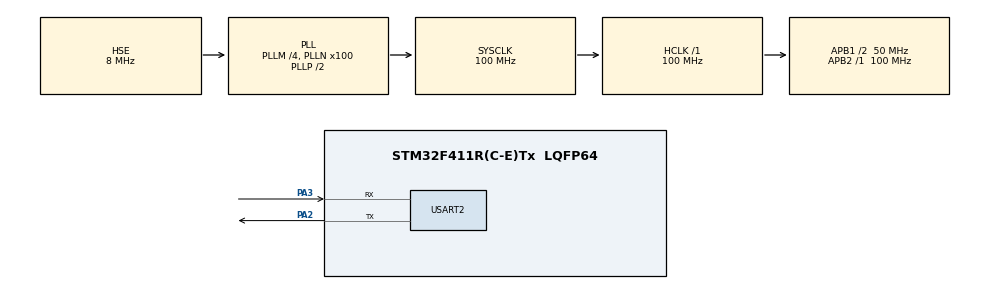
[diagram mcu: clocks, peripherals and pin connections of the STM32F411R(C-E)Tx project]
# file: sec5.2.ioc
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Mcu.Family=STM32F4
RCC.PLLSourceVirtual=RCC_PLLSOURCE_HSE
Dma.USART2_TX.1.Priority=DMA_PRIORITY_LOW
RCC.CortexFreq_Value=100000000
Dma.USART2_TX.1.FIFOMode=DMA_FIFOMODE_DISABLE
Dma.USART2_TX.1.MemInc=DMA_MINC_ENABLE
PH1\ -\ OSC_OUT.Mode=HSE-External-Clock-Source
Dma.USART2_RX.0.Direction=DMA_PERIPH_TO_MEMORY
RCC.APB1CLKDivider=RCC_HCLK_DIV2
Dma.USART2_TX.1.PeriphDataAlignment=DMA_PDATAALIGN_BYTE
NVIC.USART2_IRQn=true\:0\:0\:false\:false\:true\:true\:true
RCC.SYSCLKSource=RCC_SYSCLKSOURCE_PLLCLK
ProjectManager.StackSize=0x400
Dma.USART2_RX.0.Mode=DMA_NORMAL
PA3.Mode=Asynchronous
PA13.Signal=SYS_JTMS-SWDIO
PH0\ -\ OSC_IN.Mode=HSE-External-Clock-Source
PH0\ -\ OSC_IN.Signal=RCC_OSC_IN
ProjectManager.TargetToolchain=STM32CubeIDE
NVIC.DMA1_Stream5_IRQn=true\:0\:0\:false\:false\:true\:false\:true
Dma.USART2_RX.0.Priority=DMA_PRIORITY_LOW
Dma.USART2_RX.0.PeriphDataAlignment=DMA_PDATAALIGN_BYTE
RCC.HCLKFreq_Value=100000000
RCC.APB2TimFreq_Value=100000000
Dma.USART2_TX.1.Mode=DMA_NORMAL
RCC.LSE_VALUE=32768
RCC.AHBFreq_Value=100000000
RCC.HSE_VALUE=8000000
PH1\ -\ OSC_OUT.Signal=RCC_OSC_OUT
Dma.USART2_TX.1.PeriphInc=DMA_PINC_DISABLE
board=custom
RCC.VCOOutputFreq_Value=200000000
Dma.USART2_TX.1.Direction=DMA_MEMORY_TO_PERIPH
RCC.APB2Freq_Value=100000000
Dma.USART2_RX.0.MemDataAlignment=DMA_MDATAALIGN_BYTE
PA14.Mode=Serial_Wire
Dma.USART2_TX.1.Instance=DMA1_Stream6
Dma.USART2_RX.0.Instance=DMA1_Stream5
PA13.Mode=Serial_Wire
Mcu.Name=STM32F411R(C-E)Tx
Dma.USART2_RX.0.MemInc=DMA_MINC_ENABLE
PA2.Signal=USART2_TX
RCC.48MHZClocksFreq_Value=50000000
RCC.SYSCLKFreq_VALUE=100000000
Mcu.Package=LQFP64
Dma.USART2_RX.0.PeriphInc=DMA_PINC_DISABLE
USART2.VirtualMode=VM_ASYNC
Dma.USART2_RX.0.FIFOMode=DMA_FIFOMODE_DISABLE
PA14.Signal=SYS_JTCK-SWCLK
ProjectManager.HeapSize=0x200
RCC.HSI_VALUE=16000000
NVIC.PriorityGroup=NVIC_PRIORITYGROUP_4
RCC.PLLM=4
RCC.PLLN=100
Dma.Request1=USART2_TX
RCC.APB1TimFreq_Value=100000000
PA2.Mode=Asynchronous
Dma.USART2_TX.1.MemDataAlignment=DMA_MDATAALIGN_BYTE
RCC.APB1Freq_Value=50000000
NVIC.DMA1_Stream6_IRQn=true\:0\:0\:false\:false\:true\:false\:true
Dma.Request0=USART2_RX
PA3.Signal=USART2_RX

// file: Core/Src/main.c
/* USER CODE BEGIN Header */
/**
  ******************************************************************************
  * @file           : main.c
  * @brief          : Main program body
  ******************************************************************************
  * @attention
  *
  * <h2><center>&copy; Copyright (c) 2021 STMicroelectronics.
  * All rights reserved.</center></h2>
  *
  * This software component is licensed by ST under BSD 3-Clause license,
  * the "License"; You may not use this file except in compliance with the
  * License. You may obtain a copy of the License at:
  *                        opensource.org/licenses/BSD-3-Clause
  *
  ******************************************************************************
  */
/* USER CODE END Header */
#include "main.h"

/* USER CODE BEGIN PD */
#define LEN 50
/* USER CODE END PD */

UART_HandleTypeDef huart2;
DMA_HandleTypeDef hdma_usart2_rx;
DMA_HandleTypeDef hdma_usart2_tx;

/* USER CODE BEGIN PV */
uint8_t Buffer_Rx[LEN];
uint8_t RecCount = 0;
uint8_t RxFlag = 0;
/* USER CODE END PV */

void SystemClock_Config(void);
static void MX_GPIO_Init(void);
static void MX_DMA_Init(void);
static void MX_USART2_UART_Init(void);

int main(void)
{

  /* MCU Configuration--------------------------------------------------------*/

  /* Reset of all peripherals, Initializes the Flash interface and the Systick. */
  HAL_Init();

  /* Configure the system clock */
  SystemClock_Config();

  /* Initialize all configured peripherals */
  MX_GPIO_Init();
  MX_DMA_Init();
  MX_USART2_UART_Init();
  /* USER CODE BEGIN 2 */
  printf("enter the characters\n\r");
  __HAL_UART_ENABLE_IT(&huart2,UART_IT_IDLE);
  HAL_UART_Receive_DMA(&huart2,(uint8_t*)Buffer_Rx,LEN);
  /* USER CODE END 2 */

  /* Infinite loop */
  while (1)
  {

    /* USER CODE BEGIN 3 */
	  if (RxFlag == 1)
	  {
		  RxFlag = 0;
		  RecCount = LEN - __HAL_DMA_GET_COUNTER(&hdma_usart2_rx);
		  HAL_UART_Transmit_DMA(&huart2,(uint8_t*)Buffer_Rx,RecCount);
		  RecCount = 0;
//		  uint8_t i;
//		  for (i=0;i<sizeof(Buffer_Rx[LEN])/sizeof(uint8_t);i++)
//			  Buffer_Rx[i] = 0;

		  __HAL_DMA_DISABLE(&hdma_usart2_rx);
	  }
  }
  /* USER CODE END 3 */
}

void SystemClock_Config(void)
{
  RCC_OscInitTypeDef RCC_OscInitStruct = {0};
  RCC_ClkInitTypeDef RCC_ClkInitStruct = {0};

  /** Configure the main internal regulator output voltage
  */
  __HAL_RCC_PWR_CLK_ENABLE();
  __HAL_PWR_VOLTAGESCALING_CONFIG(PWR_REGULATOR_VOLTAGE_SCALE1);
  /** Initializes the RCC Oscillators according to the specified parameters
  * in the RCC_OscInitTypeDef structure.
  */
  RCC_OscInitStruct.OscillatorType = RCC_OSCILLATORTYPE_HSE;
  RCC_OscInitStruct.HSEState = RCC_HSE_BYPASS;
  RCC_OscInitStruct.PLL.PLLState = RCC_PLL_ON;
  RCC_OscInitStruct.PLL.PLLSource = RCC_PLLSOURCE_HSE;
  RCC_OscInitStruct.PLL.PLLM = 4;
  RCC_OscInitStruct.PLL.PLLN = 100;
  RCC_OscInitStruct.PLL.PLLP = RCC_PLLP_DIV2;
  RCC_OscInitStruct.PLL.PLLQ = 4;
  if (HAL_RCC_OscConfig(&RCC_OscInitStruct) != HAL_OK)
  {
    Error_Handler();
  }
  /** Initializes the CPU, AHB and APB buses clocks
  */
  RCC_ClkInitStruct.ClockType = RCC_CLOCKTYPE_HCLK|RCC_CLOCKTYPE_SYSCLK
                              |RCC_CLOCKTYPE_PCLK1|RCC_CLOCKTYPE_PCLK2;
  RCC_ClkInitStruct.SYSCLKSource = RCC_SYSCLKSOURCE_PLLCLK;
  RCC_ClkInitStruct.AHBCLKDivider = RCC_SYSCLK_DIV1;
  RCC_ClkInitStruct.APB1CLKDivider = RCC_HCLK_DIV2;
  RCC_ClkInitStruct.APB2CLKDivider = RCC_HCLK_DIV1;

  if (HAL_RCC_ClockConfig(&RCC_ClkInitStruct, FLASH_LATENCY_3) != HAL_OK)
  {
    Error_Handler();
  }
}

static void MX_USART2_UART_Init(void)
{

  huart2.Instance = USART2;
  huart2.Init.BaudRate = 115200;
  huart2.Init.WordLength = UART_WORDLENGTH_8B;
  huart2.Init.StopBits = UART_STOPBITS_1;
  huart2.Init.Parity = UART_PARITY_NONE;
  huart2.Init.Mode = UART_MODE_TX_RX;
  huart2.Init.HwFlowCtl = UART_HWCONTROL_NONE;
  huart2.Init.OverSampling = UART_OVERSAMPLING_16;
  if (HAL_UART_Init(&huart2) != HAL_OK)
  {
    Error_Handler();
  }

}

static void MX_DMA_Init(void)
{

  /* DMA controller clock enable */
  __HAL_RCC_DMA1_CLK_ENABLE();

  /* DMA interrupt init */
  /* DMA1_Stream5_IRQn interrupt configuration */
  HAL_NVIC_SetPriority(DMA1_Stream5_IRQn, 0, 0);
  HAL_NVIC_EnableIRQ(DMA1_Stream5_IRQn);
  /* DMA1_Stream6_IRQn interrupt configuration */
  HAL_NVIC_SetPriority(DMA1_Stream6_IRQn, 0, 0);
  HAL_NVIC_EnableIRQ(DMA1_Stream6_IRQn);

}

static void MX_GPIO_Init(void)
{

  /* GPIO Ports Clock Enable */
  __HAL_RCC_GPIOH_CLK_ENABLE();
  __HAL_RCC_GPIOA_CLK_ENABLE();

}

/* USER CODE BEGIN 4 */
int __io_putchar(int ch)
{
	HAL_UART_Transmit(&huart2, (uint8_t*)&ch,1,HAL_MAX_DELAY);
    return ch;
}
void HAL_UART_RxCpltCallback (UART_HandleTypeDef * huart)
{
	if (huart ->Instance == USART2)
	{

		HAL_UART_Receive_DMA(&huart2,(uint8_t*)Buffer_Rx,LEN);
	}
}
void HAL_UART_IdleCpltCallback(UART_HandleTypeDef * huart)
{
	RxFlag =1;
}
void HAL_UART_TxCpltCallback (UART_HandleTypeDef * huart)
{
	if (huart ->Instance == USART2)
	{

		printf("U6972739\n\r");
	}
}
/* USER CODE END 4 */

void Error_Handler(void)
{
  __disable_irq();
  while (1)
  {
  }
}

/************************ (C) COPYRIGHT STMicroelectronics *****END OF FILE****/
